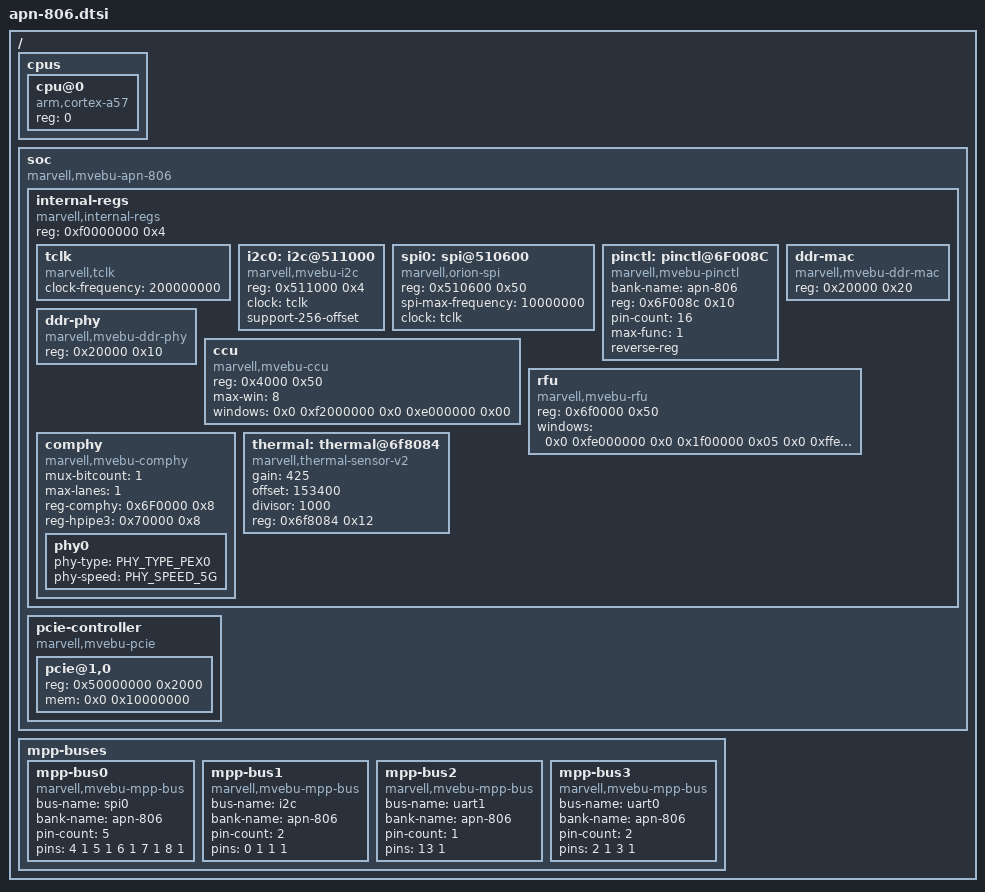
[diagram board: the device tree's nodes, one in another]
/*
 * ***************************************************************************
 * Copyright (C) 2015 Marvell International Ltd.
 * ***************************************************************************
 * This program is free software: you can redistribute it and/or modify it
 * under the terms of the GNU General Public License as published by the Free
 * Software Foundation, either version 2 of the License, or any later version.
 *
 * This program is distributed in the hope that it will be useful,
 * but WITHOUT ANY WARRANTY; without even the implied warranty of
 * MERCHANTABILITY or FITNESS FOR A PARTICULAR PURPOSE.  See the
 * GNU General Public License for more details.
 *
 * You should have received a copy of the GNU General Public License
 * along with this program.  If not, see <http://www.gnu.org/licenses/>.
 * ***************************************************************************
 */

#include <dt-bindings/comphy/comphy_data.h>
/ {

	cpus {
		#address-cells = <1>;
		#size-cells = <0>;
		cpu@0 {
			device_type = "cpu";
			compatible = "arm,cortex-a57";
			reg = <0>;
		};
	};

	soc {
		compatible = "marvell,mvebu-apn-806";
		#address-cells = <1>;
		#size-cells = <0>;

		internal-regs {
			compatible = "marvell,internal-regs";
			#address-cells = <1>;
			#size-cells = <1>;
			reg = <0xf0000000 0x4>;

			tclk: tclk {
				compatible = "marvell,tclk";
				#clock-cells = <0>;
				clock-frequency = <200000000>;
			};

			i2c0: i2c@511000 {
				compatible = "marvell,mvebu-i2c";
				reg = <0x511000 0x4>;
				clock = <&tclk>;
				support-256-offset;
				status = "okay";
			};

			spi0: spi@510600 {
				compatible = "marvell,orion-spi";
				reg = <0x510600 0x50>;
				spi-max-frequency = <10000000>;
				clock = <&tclk>;
				status = "okay";
			};

			pinctl: pinctl@6F008C {
				compatible = "marvell,mvebu-pinctl";
				bank-name ="apn-806";
				reg = <0x6F008c 0x10>;
				pin-count = <16>;
				max-func = <1>;
				reverse-reg;
			};

			ddr-mac {
				compatible = "marvell,mvebu-ddr-mac";
				reg = <0x20000 0x20>;
				status = "okay";
			};

			ddr-phy {
				compatible = "marvell,mvebu-ddr-phy";
				reg = <0x20000 0x10>;
				status = "okay";
			};

			ccu {
				compatible = "marvell,mvebu-ccu";
				reg = <0x4000 0x50>;
				max-win = <8>;
				windows = <0x0 0xf2000000 0x0 0xe000000 0x00 /* IO window */>;
			};

			rfu {
				compatible = "marvell,mvebu-rfu";
				reg = <0x6f0000 0x50>;
				windows = <0x0 0xfe000000 0x0 0x1f00000 0x05 /* PCIe window 31Mb for PCIe port*/
					0x0 0xffe00000 0x0 0x100000 0x03 /* PCI-REG window 64Kb for PCIe-reg*/>;
			};

			comphy {
				compatible = "marvell,mvebu-comphy", "marvell,comphy-ap806";
				mux-bitcount = <1>;
				max-lanes = <1>;
				reg-comphy = <0x6F0000 0x8>;
				reg-hpipe3 = <0x70000 0x8>;
				phy0 {
					phy-type = <PHY_TYPE_PEX0>;
					phy-speed = <PHY_SPEED_5G>;
				};
			};

			thermal: thermal@6f8084 {
				compatible = "marvell,thermal-sensor-v2";
				gain = <425>;
				offset = <153400>;
				divisor = <1000>;
				reg = <0x6f8084 0x12>;
				status = "okay";
			};

		};
		pcie-controller {
			#address-cells = <1>;
			#size-cells = <1>;
			compatible = "marvell,mvebu-pcie";

			pcie@1,0 {
				reg = <0x50000000 0x2000>;
				mem = <0x0 0x10000000>;
				status = "okay";
			};
		};
	};
	/* This should go only into devel boards */
	mpp-buses {
		mpp-bus0 {
			compatible = "marvell,mvebu-mpp-bus";
			bus-name = "spi0";
			bank-name = "apn-806";
			pin-count = <5>;
			pins = <4 1  5 1  6 1  7 1  8 1>;
		};
		mpp-bus1 {
			compatible = "marvell,mvebu-mpp-bus";
			bus-name = "i2c";
			bank-name = "apn-806";
			pin-count = <2>;
			pins = <0 1  1 1>;
		};
		mpp-bus2 {
			/* the RX pin is directly connected to uart1 */
			compatible = "marvell,mvebu-mpp-bus";
			bus-name = "uart1";
			bank-name = "apn-806";
			pin-count = <1>;
			pins = <13 1>;
		};
		mpp-bus3 {
			compatible = "marvell,mvebu-mpp-bus";
			bus-name = "uart0";
			bank-name = "apn-806";
			pin-count = <2>;
			pins = <2 1  3 1>;
		};
	};
};
